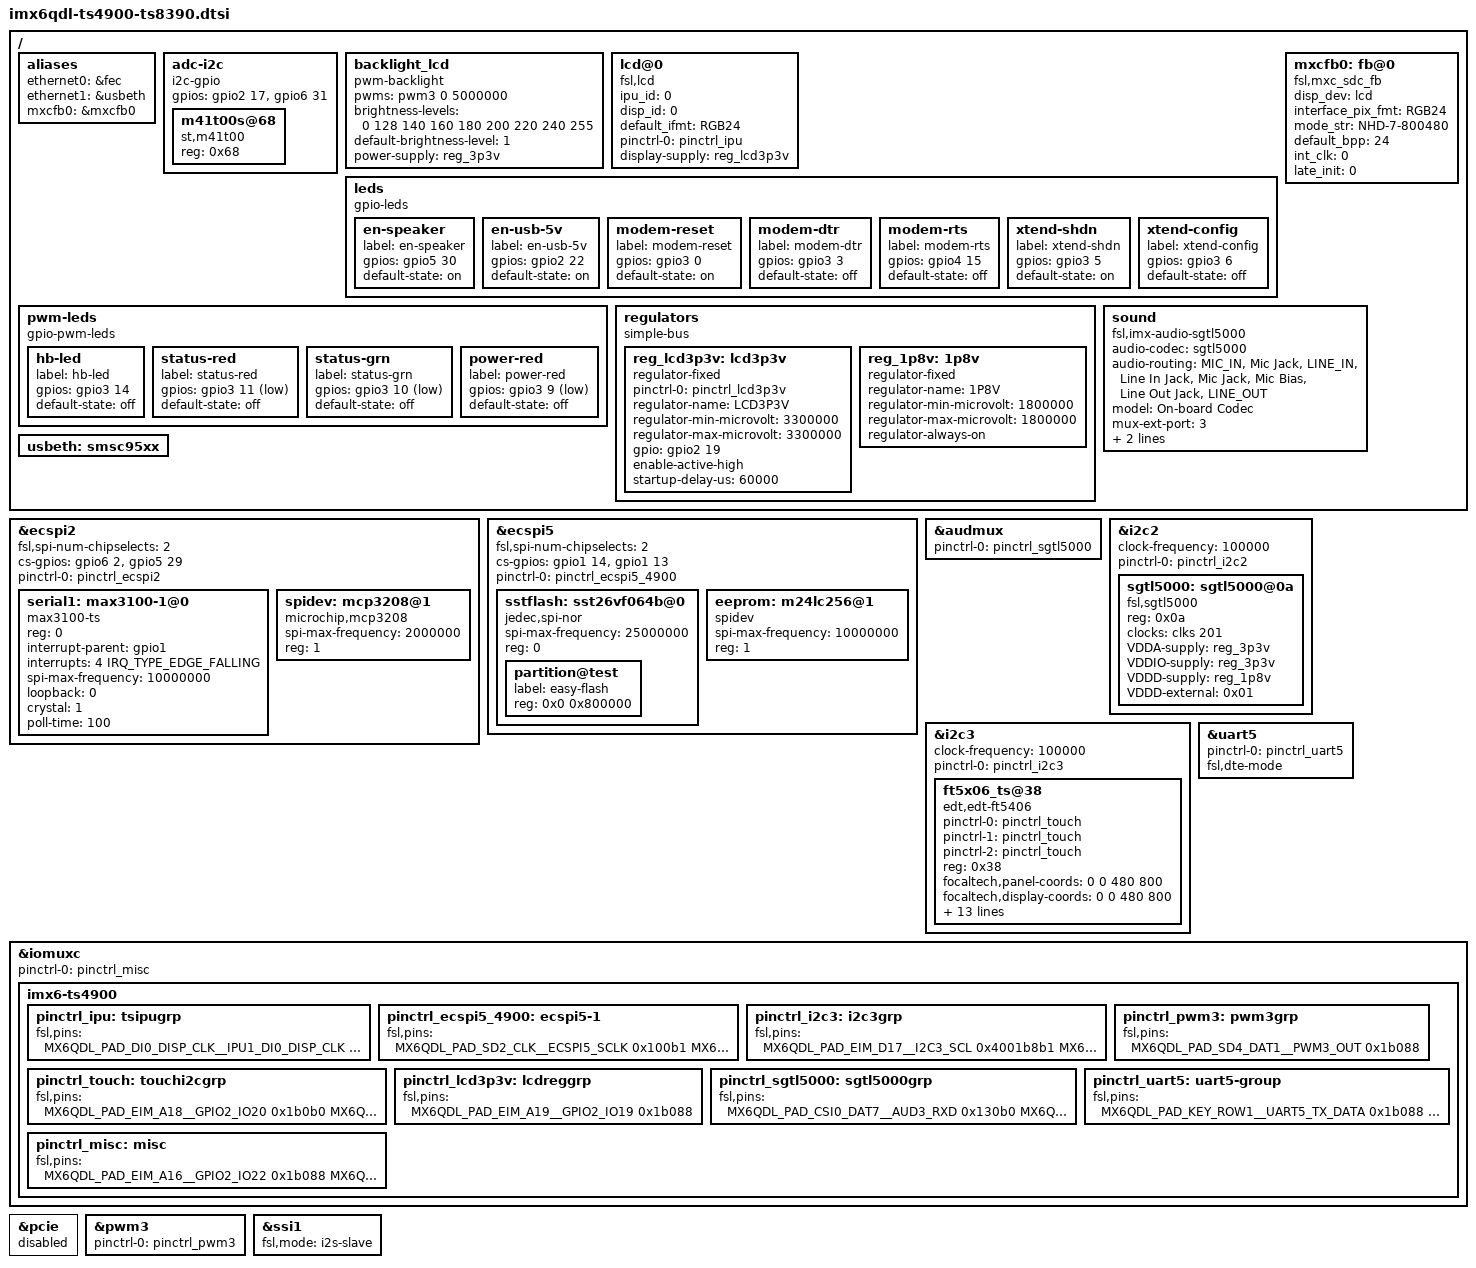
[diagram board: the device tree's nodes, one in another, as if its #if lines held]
/*
 * Copyright 2017 Technologic Systems
 *
 * This file is dual-licensed: you can use it either under the terms
 * of the GPL or the X11 license, at your option. Note that this dual
 * licensing only applies to this file, and not this project as a
 * whole.
 *
 *  a) This file is free software; you can redistribute it and/or
 *     modify it under the terms of the GNU General Public License
 *     version 2 as published by the Free Software Foundation.
 *
 *     This file is distributed in the hope that it will be useful
 *     but WITHOUT ANY WARRANTY; without even the implied warranty of
 *     MERCHANTABILITY or FITNESS FOR A PARTICULAR PURPOSE.  See the
 *     GNU General Public License for more details.
 *
 * Or, alternatively
 *
 *  b) Permission is hereby granted, free of charge, to any person
 *     obtaining a copy of this software and associated documentation
 *     files (the "Software"), to deal in the Software without
 *     restriction, including without limitation the rights to use
 *     copy, modify, merge, publish, distribute, sublicense, and/or
 *     sell copies of the Software, and to permit persons to whom the
 *     Software is furnished to do so, subject to the following
 *     conditions:
 *
 *     The above copyright notice and this permission notice shall be
 *     included in all copies or substantial portions of the Software.
 *
 *     THE SOFTWARE IS PROVIDED , WITHOUT WARRANTY OF ANY KIND
 *     EXPRESS OR IMPLIED, INCLUDING BUT NOT LIMITED TO THE WARRANTIES
 *     OF MERCHANTABILITY, FITNESS FOR A PARTICULAR PURPOSE AND
 *     NONINFRINGEMENT. IN NO EVENT SHALL THE AUTHORS OR COPYRIGHT
 *     HOLDERS BE LIABLE FOR ANY CLAIM, DAMAGES OR OTHER LIABILITY
 *     WHETHER IN AN ACTION OF CONTRACT, TORT OR OTHERWISE, ARISING
 *     FROM, OUT OF OR IN CONNECTION WITH THE SOFTWARE OR THE USE OR
 *     OTHER DEALINGS IN THE SOFTWARE.
 */

#include "imx6qdl-ts4900.dtsi"
#include <dt-bindings/interrupt-controller/irq.h>

/ {
	aliases {
		ethernet0 = &fec;
		ethernet1 = &usbeth;
		mxcfb0 = &mxcfb0;
		/*i2c3 = &adc_i2c;*/
	};
#ifdef NoHwClock /*We don't really need this because the ts4900 has one*/
	adc-i2c {
		compatible = "i2c-gpio";
		gpios = <&gpio2 17 0>, /* sda */
				<&gpio6 31 0>; /* scl */
		#address-cells = <1>;
		#size-cells = <0>;

		m41t00s@68 {
			compatible = "st,m41t00";
			reg = <0x68>;
		};
	};
#endif
	backlight_lcd {
		compatible = "pwm-backlight";
		pwms = <&pwm3 0 5000000>;
		brightness-levels = <0 128 140 160 180 200 220 240 255>;
		default-brightness-level = <1>;
		power-supply = <&reg_3p3v>;
	};

	lcd@0 {
		compatible = "fsl,lcd";
		ipu_id = <0>;
		disp_id = <0>;
		default_ifmt = "RGB24";
		pinctrl-names = "default";
		pinctrl-0 = <&pinctrl_ipu>;
		status = "okay";
		display-supply = <&reg_lcd3p3v>;
	};

	leds {
		compatible = "gpio-leds";

		/* These are intended as userspace controlled IO.  In this
		 * kernel version LEDs are the best interface I can find to 
		 * allow both userspace control and a default value.
		 */
		en-speaker {
			label = "en-speaker";
			gpios = <&gpio5 30 0>;
			default-state = "on";
		};

		en-usb-5v {
			label = "en-usb-5v";
			gpios = <&gpio2 22 0>;
			default-state = "on";
		};

		//hb-led {
		//	label = "hb-led";
		//	gpios = <&gpio3 14 0>;
		//	default-state = "on";
		//};

        modem-reset {
            label = "modem-reset";
            gpios = <&gpio3 0 0>;
            default-state = "on";
        };

        modem-dtr {
            label = "modem-dtr";
            gpios = <&gpio3 3 0>;
            default-state = "off";
        };

        modem-rts {
            label = "modem-rts";
            gpios = <&gpio4 15 0>;
            default-state = "off";
        };

        xtend-shdn {
            label = "xtend-shdn";
            gpios = <&gpio3 5 0>;
            default-state = "on";
        };

        xtend-config {
            label = "xtend-config";
            gpios = <&gpio3 6 0>;
            default-state = "off";
        };

	};

	pwm-leds {
		compatible = "gpio-pwm-leds";

		hb-led {
			label = "hb-led";
			gpios = <&gpio3 14 0>;
			default-state = "off";
		};

        status-red {
            label = "status-red";
            gpios = <&gpio3 11 1>;
            default-state = "off";
        };

        status-grn {
            label = "status-grn";
            gpios = <&gpio3 10 1>;
            default-state = "off";
        };

        power-red {
            label = "power-red";
            gpios = <&gpio3 9 1>;
            default-state = "off";
        };
        
    };

	mxcfb0: fb@0 {
		compatible = "fsl,mxc_sdc_fb";
		disp_dev = "lcd";
		interface_pix_fmt = "RGB24";
		mode_str ="NHD-7-800480";
		default_bpp = <24>;
		int_clk = <0>;
		late_init = <0>;
		status = "okay";
	};

	regulators {
		compatible = "simple-bus";

		reg_lcd3p3v: lcd3p3v {
			compatible = "regulator-fixed";
			pinctrl-names = "default";
			pinctrl-0 = <&pinctrl_lcd3p3v>;
			regulator-name = "LCD3P3V";
			regulator-min-microvolt = <3300000>;
			regulator-max-microvolt = <3300000>;
			gpio = <&gpio2 19 0>;
			enable-active-high;
			startup-delay-us = <60000>;
		};

		reg_1p8v: 1p8v {
			compatible = "regulator-fixed";
			regulator-name = "1P8V";
			regulator-min-microvolt = <1800000>;
			regulator-max-microvolt = <1800000>;
			regulator-always-on;
		};
	};

	sound {
	    compatible = "fsl,imx-audio-sgtl5000";
		audio-codec = <&sgtl5000>;
		audio-routing =
			"MIC_IN", "Mic Jack",
            "LINE_IN", "Line In Jack",
			"Mic Jack", "Mic Bias",
			"Line Out Jack", "LINE_OUT";
		model = "On-board Codec";
		mux-ext-port = <3>;
		mux-int-port = <1>;
		ssi-controller = <&ssi1>;
	};

	usbeth: smsc95xx {
		status = "okay";
	};
};

#ifdef AERCONNECT
&ecspi2 {
	fsl,spi-num-chipselects = <2>;
	cs-gpios = <&gpio6 2 0>,<&gpio5 29 0>;
	pinctrl-names = "default";
	pinctrl-0 = <&pinctrl_ecspi2>;
	status = "okay";

	serial1: max3100-1@0 {
		compatible = "max3100-ts";
		reg = <0>;
		interrupt-parent = <&gpio1>;
		interrupts = <4 IRQ_TYPE_EDGE_FALLING>;
		spi-max-frequency = <10000000>;
		loopback = <0>;
		crystal = <1>;
		poll-time = <100>;
	};
	spidev: mcp3208@1 {
		compatible = "microchip,mcp3208";
		spi-max-frequency = <2000000>;
		reg = <1>;
	};
};
#endif

#ifdef USESPI5
&ecspi5 {
	fsl,spi-num-chipselects = <2>;
	cs-gpios = <&gpio1 14 0>, <&gpio1 13 0>;
	pinctrl-names = "default";
	pinctrl-0 = <&pinctrl_ecspi5_4900>;
	status = "okay";
	sstflash: sst26vf064b@0 {
		compatible = "jedec,spi-nor";
		spi-max-frequency = <25000000>;
		reg = <0>;
		#address-cells = <1>;
		#size-cells = <1>;
		partition@test {
			label = "easy-flash";
			reg = <0x0 0x800000>;
		};			
	};
#if 1
	eeprom: m24lc256@1 {
		compatible = "spidev";
		spi-max-frequency = <10000000>;
		reg = <1>;
	};
#else
	eeprom: m24lc256@1 {
		compatible = "at,at25";
		reg = <1>;
		spi-max-frequency = <8000000>;
		address-width = <16>;	
		pagesize = <64>;
		size = <32768>;
	};
#endif

};
#endif

&audmux {
	status = "okay";
	pinctrl-names = "default";
	pinctrl-0 = <&pinctrl_sgtl5000>;
};

&i2c2 {
	status = "okay";
	clock-frequency = <100000>;
	pinctrl-names = "default";
	pinctrl-0 = <&pinctrl_i2c2>;

	sgtl5000: sgtl5000@0a {
		compatible = "fsl,sgtl5000";
		reg = <0x0a>;
		clocks = <&clks 201>;
		VDDA-supply = <&reg_3p3v>;
		VDDIO-supply = <&reg_3p3v>;
		VDDD-supply = <&reg_1p8v>;
		VDDD-external = <0x01>;
	};
};

&i2c3 {
	clock-frequency = <100000>;
	pinctrl-names = "default";
	pinctrl-0 = <&pinctrl_i2c3>;
	status = "okay";
	
	ft5x06_ts@38 {
		pinctrl-names = "pmx_ts_active", "pmx_ts_suspend", "pmx_ts_release";
		pinctrl-0 = <&pinctrl_touch>;
		pinctrl-1 = <&pinctrl_touch>;
		pinctrl-2 = <&pinctrl_touch>;
		
		//compatible = "focaltech,5x06", "ft5x06_ts";
        compatible = "edt,edt-ft5406", "edt,edt-ft5x06";
		reg = <0x38>;
		focaltech,panel-coords = <0 0 480 800>;
		focaltech,display-coords = <0 0 480 800>;
		focaltech,reset-gpio = <&gpio2 25 GPIO_ACTIVE_LOW>;
		focaltech,irq-gpio = <&gpio2 20 IRQ_TYPE_EDGE_FALLING>;
		focaltech,group-id = <1000>; // no clue what this one's supposed to be either
		focaltech,hard-reset-delay-ms = <750>; // don't know what this is for yet.
		focaltech,soft-reset-delay-ms = <250>; // or this.
		focaltech,num-max-touches = <4>; // I think the max for this one is 5.
		
		// I'm thinking this one's optional -> links to pdata->info.delay_aa
		focaltech,fw-delay-aa-ms = <5>; // No clue what the default for this one should be, or what this does.
		focaltech,fw-delay-55-ms = <5>; // same here.
		focaltech,family-id = <0x00000055>;
		touchscreen-size-x = <800>;
		touchscreen-size-y = <480>;
		interrupt-parent = <&gpio2>;
		interrupts = <20 IRQ_TYPE_EDGE_FALLING>;
	};
};

&uart5 {
    status = "okay";
	pinctrl-names = "default";
	pinctrl-0 = <&pinctrl_uart5>;
    //fsl,uart-has-rtscts;
    fsl,dte-mode;
};

&iomuxc {
	pinctrl-names = "default";
	pinctrl-0 = <&pinctrl_misc>;

	imx6-ts4900 {
		pinctrl_ipu: tsipugrp {
			fsl,pins = <
				MX6QDL_PAD_DI0_DISP_CLK__IPU1_DI0_DISP_CLK	0x38
				MX6QDL_PAD_DI0_PIN15__IPU1_DI0_PIN15		0xe0 /* DE */
				MX6QDL_PAD_DI0_PIN2__IPU1_DI0_PIN02		0xe0 /* Hsync */
				MX6QDL_PAD_DI0_PIN3__IPU1_DI0_PIN03		0xe0 /* Vsync */
				MX6QDL_PAD_DISP0_DAT0__IPU1_DISP0_DATA00	0xe0
				MX6QDL_PAD_DISP0_DAT1__IPU1_DISP0_DATA01	0xe0
				MX6QDL_PAD_DISP0_DAT2__IPU1_DISP0_DATA02	0xe0
				MX6QDL_PAD_DISP0_DAT3__IPU1_DISP0_DATA03	0xe0
				MX6QDL_PAD_DISP0_DAT4__IPU1_DISP0_DATA04	0xe0
				MX6QDL_PAD_DISP0_DAT5__IPU1_DISP0_DATA05	0xe0
				MX6QDL_PAD_DISP0_DAT6__IPU1_DISP0_DATA06	0xe0
				MX6QDL_PAD_DISP0_DAT7__IPU1_DISP0_DATA07	0xe0
				MX6QDL_PAD_DISP0_DAT8__IPU1_DISP0_DATA08	0xe0
				MX6QDL_PAD_DISP0_DAT9__IPU1_DISP0_DATA09	0xe0
				MX6QDL_PAD_DISP0_DAT10__IPU1_DISP0_DATA10	0xe0
				MX6QDL_PAD_DISP0_DAT11__IPU1_DISP0_DATA11	0xe0
				MX6QDL_PAD_DISP0_DAT12__IPU1_DISP0_DATA12	0xe0
				MX6QDL_PAD_DISP0_DAT13__IPU1_DISP0_DATA13	0xe0
				MX6QDL_PAD_DISP0_DAT14__IPU1_DISP0_DATA14	0xe0
				MX6QDL_PAD_DISP0_DAT15__IPU1_DISP0_DATA15	0xe0
				MX6QDL_PAD_DISP0_DAT16__IPU1_DISP0_DATA16	0xe0
				MX6QDL_PAD_DISP0_DAT17__IPU1_DISP0_DATA17	0xe0
				MX6QDL_PAD_DISP0_DAT18__IPU1_DISP0_DATA18	0xe0
				MX6QDL_PAD_DISP0_DAT19__IPU1_DISP0_DATA19	0xe0
				MX6QDL_PAD_DISP0_DAT20__IPU1_DISP0_DATA20	0xe0
				MX6QDL_PAD_DISP0_DAT21__IPU1_DISP0_DATA21	0xe0
				MX6QDL_PAD_DISP0_DAT22__IPU1_DISP0_DATA22	0xe0
				MX6QDL_PAD_DISP0_DAT23__IPU1_DISP0_DATA23	0xe0
			>;
		};

#ifdef USESPI5
        pinctrl_ecspi5_4900: ecspi5-1 {
                fsl,pins = <
                        MX6QDL_PAD_SD2_CLK__ECSPI5_SCLK      0x100b1 /* Clock */
                        MX6QDL_PAD_SD2_CMD__ECSPI5_MOSI      0x100b1 /* MOSI */
                        MX6QDL_PAD_SD2_DAT0__ECSPI5_MISO      0x100b1 /* MISO */
                        MX6QDL_PAD_SD2_DAT1__GPIO1_IO14      0x100b1 /* 25n CS0 */
				        MX6QDL_PAD_SD2_DAT2__GPIO1_IO13       0x100b1 /* EEPROM CS1 */
                >;
        };
 	   
#endif


		pinctrl_i2c3: i2c3grp {
			fsl,pins = <
				MX6QDL_PAD_EIM_D17__I2C3_SCL	0x4001b8b1
				MX6QDL_PAD_EIM_D18__I2C3_SDA	0x4001b8b1
			>;
		};
		
		pinctrl_touch: touchi2cgrp {
			fsl,pins = <
				MX6QDL_PAD_EIM_A18__GPIO2_IO20	0x1b0b0
				MX6QDL_PAD_EIM_OE__GPIO2_IO25	0x4001b8b1 /* RESET */
			>;
		};
#if 0
		pinctrl_touch: touchspigrp {
			fsl,pins = <
				MX6QDL_PAD_EIM_DA11__GPIO3_IO11		0x1b088 /* TOUCH_WAKE# */
				MX6QDL_PAD_EIM_DA12__GPIO3_IO12		0x1b088 /* TOUCH_CS# */
				MX6QDL_PAD_EIM_DA13__GPIO3_IO13		0x1b088 /* TOUCH_MISO */
				MX6QDL_PAD_EIM_DA14__GPIO3_IO14		0x1b088 /* TOUCH_MOSI */
				MX6QDL_PAD_EIM_DA15__GPIO3_IO15		0x1b088 /* TOUCH_CLK */
			>;
		};

		/*
			I2C touch panel, uses module I2C3. The pins are SCL: CN1-56, SDA: CN1-58.
			The interrupt pin is CN1-81 and reset is CN1-83.
			J3 in schematic.
		*/
#endif

		pinctrl_pwm3: pwm3grp {
			fsl,pins = <
				MX6QDL_PAD_SD4_DAT1__PWM3_OUT		0x1b088
			>;
		};

		pinctrl_lcd3p3v: lcdreggrp {
			fsl,pins = <
				MX6QDL_PAD_EIM_A19__GPIO2_IO19		0x1b088 /* EN_LCD_3.3V */
			>;
		};

		pinctrl_sgtl5000: sgtl5000grp {
			fsl,pins = <
				MX6QDL_PAD_CSI0_DAT7__AUD3_RXD		0x130b0
				MX6QDL_PAD_CSI0_DAT4__AUD3_TXC		0x130b0
				MX6QDL_PAD_CSI0_DAT5__AUD3_TXD		0x110b0
				MX6QDL_PAD_CSI0_DAT6__AUD3_TXFS		0x130b0
				MX6QDL_PAD_GPIO_0__CCM_CLKO1		0x130b0 /* Audio CLK */
			>;
		};

#if 0
		pinctrl_anamux: anamuxgrp {
			fsl,pins = <
				MX6QDL_PAD_EIM_DA10__GPIO3_IO10		0x1b088 /* AN_SEL */
				MX6QDL_PAD_EIM_BCLK__GPIO6_IO31		0x1b088 /* ADC_CLK */
				MX6QDL_PAD_EIM_A18__GPIO2_IO20		0x1b088 /* ADC_DAT */
			>;
		};
#endif
#ifdef AERCONNECT
		pinctrl_uart5: uart5-group {
			fsl,pins = <
				MX6QDL_PAD_KEY_ROW1__UART5_TX_DATA	0x1b088
				MX6QDL_PAD_KEY_COL1__UART5_RX_DATA	0x1b088
                //MX6QDL_PAD_KEY_ROW4__UART5_RTS_B    0x1b088
                //MX6QDL_PAD_KEY_COL4__UART5_CTS_B    0x1b088
                MX6QDL_PAD_KEY_ROW4__GPIO4_IO15     0x1b088
                MX6QDL_PAD_KEY_COL4__GPIO4_IO14     0x1b088
			>;
		};
#endif
		pinctrl_misc: misc {
			fsl,pins = <
				MX6QDL_PAD_EIM_A16__GPIO2_IO22		0x1b088 /* EN_USB_5V# */
				MX6QDL_PAD_EIM_A17__GPIO2_IO21		0x1b088 /* OFF_BD_RESET# */

				MX6QDL_PAD_EIM_A24__GPIO5_IO04		0x1b088 /* DIO_00/OUT_0 */
				MX6QDL_PAD_EIM_A23__GPIO6_IO06		0x1b088 /* DIO_01/OUT_1 */
				MX6QDL_PAD_EIM_A22__GPIO2_IO16		0x1b088 /* DIO_02/OUT_2 */
				MX6QDL_PAD_EIM_EB1__GPIO2_IO29		0x1b088 /* DIO_23/OUT_3 */
				MX6QDL_PAD_EIM_CS0__GPIO2_IO23		0x1b088 /* DIO_24/OUT_4 */
				MX6QDL_PAD_EIM_LBA__GPIO2_IO27		0x1b088 /* DIO_26/OUT_5 */
				MX6QDL_PAD_EIM_DA8__GPIO3_IO08		0x1b088 /* DIO_27/OUT_6 */
				MX6QDL_PAD_EIM_DA9__GPIO3_IO09		0x1b088 /* DIO_28/OUT_7 */
				MX6QDL_PAD_CSI0_MCLK__GPIO5_IO19	0x1b088 /* OUT_8 */
				MX6QDL_PAD_EIM_A21__GPIO2_IO17		0x1b088 /* DIO_08/IN_0 */
				MX6QDL_PAD_EIM_WAIT__GPIO5_IO00		0x1b088 /* DIO_22/IN_2 */
				MX6QDL_PAD_EIM_A20__GPIO2_IO18		0x1b088 /* DIO_04/IN_4 */
				MX6QDL_PAD_GPIO_19__GPIO4_IO05		0x1b088 /* DIO_29/IN_5 */
				MX6QDL_PAD_CSI0_DAT17__GPIO6_IO03	0x1b088 /* DIO_20/IN_6 */
				MX6QDL_PAD_CSI0_PIXCLK__GPIO5_IO18	0x1b088 /* DIO_21/IN_7 */
				MX6QDL_PAD_GPIO_17__GPIO7_IO12		0x1b088 /* DIO_17/IN_8 */
				MX6QDL_PAD_SD3_RST__GPIO7_IO08		0x1b088 /* DIO_43/IN_9 */
				MX6QDL_PAD_GPIO_16__GPIO7_IO11		0x1b088 /* DIO_49/IN_10 */
				MX6QDL_PAD_SD4_DAT7__GPIO2_IO15		0x1b088 /* DIO_52/IN_11 */
				MX6QDL_PAD_CSI0_DAT12__GPIO5_IO30	0x1b088 /* EN_SPKR */

				MX6QDL_PAD_GPIO_5__GPIO1_IO05		0x1b088 /* DIO_20/IN_6 */
				MX6QDL_PAD_GPIO_9__GPIO1_IO09		0x1b088 /* DIO_43/IN_9 */
                MX6QDL_PAD_EIM_DA3__GPIO3_IO03      0x1b088
                MX6QDL_PAD_EIM_DA11__GPIO3_IO11     0x1b088
                MX6QDL_PAD_EIM_DA9__GPIO3_IO09      0x1b088
                MX6QDL_PAD_EIM_DA10__GPIO3_IO10     0x1b088

			>;
		};
	};
};

&pcie {
	status = "disabled";
};

&pwm3 {
	pinctrl-names = "default";
	pinctrl-0 = <&pinctrl_pwm3>;
	status = "okay";
};

&ssi1 {
    fsl,mode = "i2s-slave";
	status = "okay";
};
